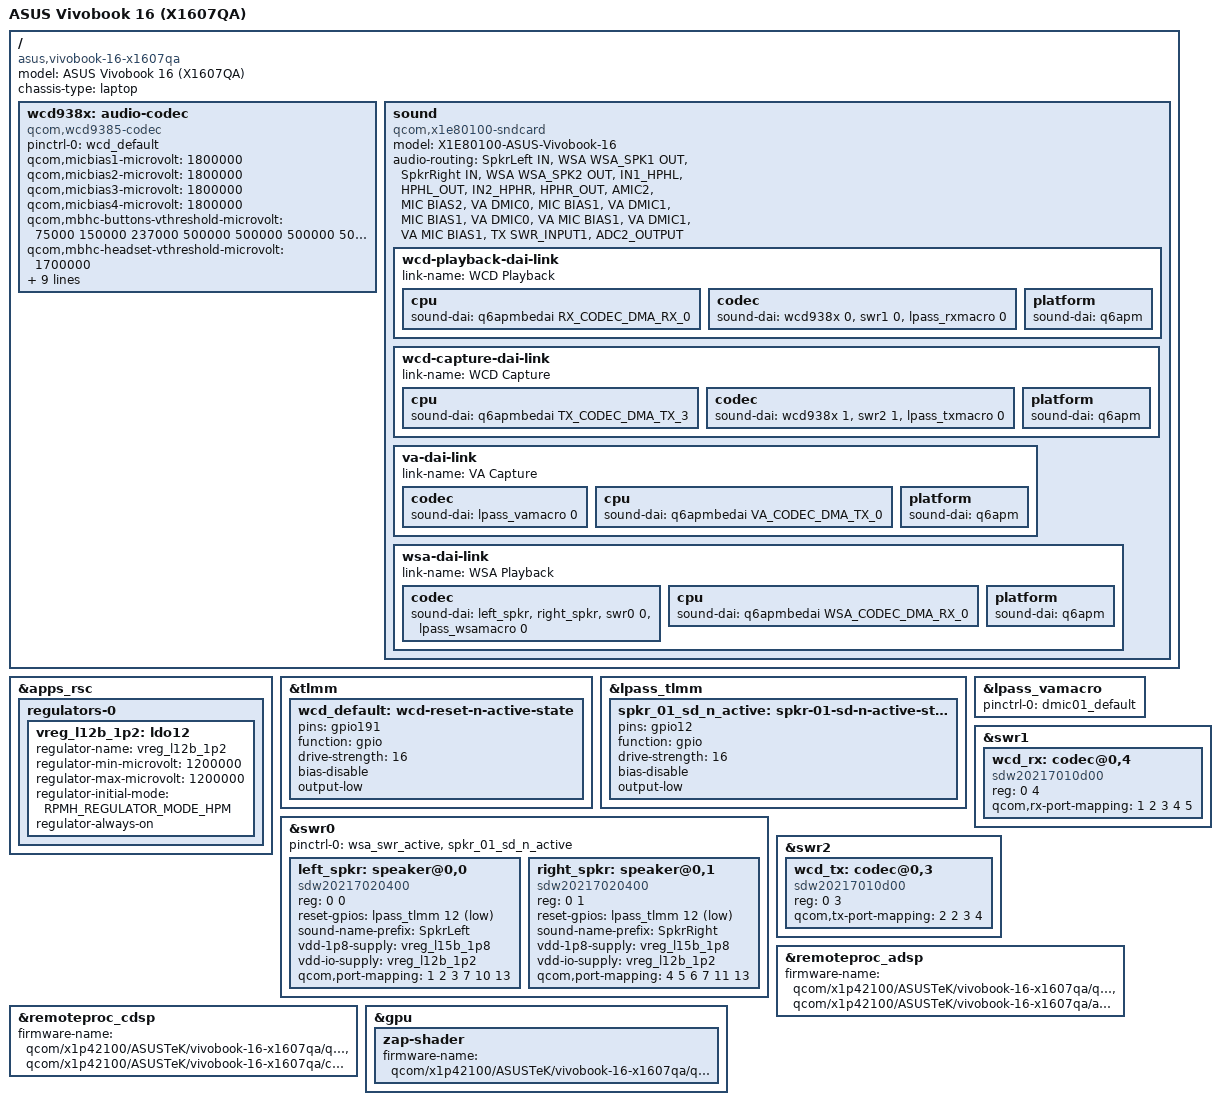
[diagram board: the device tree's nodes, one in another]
// SPDX-License-Identifier: BSD-3-Clause
/* Hybrid device tree for ASUS Vivobook 16 X1607QA (X1P-42-100).
 * Base: proven x1p42100-asus-vivobook-s15 (panel, USB, boot path).
 * Transplanted from x126100-asus-vivobook-16: audio stack
 * (WCD9385 codec, WSA8845 speakers, soundwire, sndcard) + firmware paths.
 */

/dts-v1/;

#include "purwa.dtsi"
#include "x1-asus-vivobook-s15.dtsi"

/ {
	model = "ASUS Vivobook 16 (X1607QA)";
	compatible = "asus,vivobook-16-x1607qa", "qcom,x1p42100";
	chassis-type = "laptop";
};

/* Speaker VDD-IO rail, from vivobook-16 board regulators */
&apps_rsc {
	regulators-0 {
		vreg_l12b_1p2: ldo12 {
			regulator-name = "vreg_l12b_1p2";
			regulator-min-microvolt = <1200000>;
			regulator-max-microvolt = <1200000>;
			regulator-initial-mode = <RPMH_REGULATOR_MODE_HPM>;
			regulator-always-on;
		};
	};
};

&tlmm {
	wcd_default: wcd-reset-n-active-state {
		pins = "gpio191";
		function = "gpio";
		drive-strength = <16>;
		bias-disable;
		output-low;
	};
};

&lpass_tlmm {
	spkr_01_sd_n_active: spkr-01-sd-n-active-state {
		pins = "gpio12";
		function = "gpio";
		drive-strength = <16>;
		bias-disable;
		output-low;
	};
};

&lpass_vamacro {
	pinctrl-0 = <&dmic01_default>;
	pinctrl-names = "default";
};

/ {
	wcd938x: audio-codec {
		compatible = "qcom,wcd9385-codec";

		pinctrl-0 = <&wcd_default>;
		pinctrl-names = "default";

		qcom,micbias1-microvolt = <1800000>;
		qcom,micbias2-microvolt = <1800000>;
		qcom,micbias3-microvolt = <1800000>;
		qcom,micbias4-microvolt = <1800000>;
		qcom,mbhc-buttons-vthreshold-microvolt =
			<75000 150000 237000 500000 500000 500000 500000 500000>;
		qcom,mbhc-headset-vthreshold-microvolt = <1700000>;
		qcom,mbhc-headphone-vthreshold-microvolt = <50000>;
		qcom,rx-device = <&wcd_rx>;
		qcom,tx-device = <&wcd_tx>;

		reset-gpios = <&tlmm 191 GPIO_ACTIVE_LOW>;

		vdd-buck-supply = <&vreg_l15b_1p8>;
		vdd-rxtx-supply = <&vreg_l15b_1p8>;
		vdd-io-supply = <&vreg_l15b_1p8>;
		vdd-mic-bias-supply = <&vreg_bob1>;

		#sound-dai-cells = <1>;
	};

	sound {
		compatible = "qcom,x1e80100-sndcard";
		model = "X1E80100-ASUS-Vivobook-16";
		audio-routing = "SpkrLeft IN", "WSA WSA_SPK1 OUT",
						"SpkrRight IN", "WSA WSA_SPK2 OUT",
						"IN1_HPHL", "HPHL_OUT",
						"IN2_HPHR", "HPHR_OUT",
						"AMIC2", "MIC BIAS2",
						"VA DMIC0", "MIC BIAS1",
						"VA DMIC1", "MIC BIAS1",
						"VA DMIC0", "VA MIC BIAS1",
						"VA DMIC1", "VA MIC BIAS1",
						"TX SWR_INPUT1", "ADC2_OUTPUT";

		wcd-playback-dai-link {
			link-name = "WCD Playback";

			cpu {
				sound-dai = <&q6apmbedai RX_CODEC_DMA_RX_0>;
			};

			codec {
				sound-dai = <&wcd938x 0>, <&swr1 0>, <&lpass_rxmacro 0>;
			};

			platform {
				sound-dai = <&q6apm>;
			};
		};

		wcd-capture-dai-link {
			link-name = "WCD Capture";

			cpu {
				sound-dai = <&q6apmbedai TX_CODEC_DMA_TX_3>;
			};

			codec {
				sound-dai = <&wcd938x 1>, <&swr2 1>, <&lpass_txmacro 0>;
			};

			platform {
				sound-dai = <&q6apm>;
			};
		};

		va-dai-link {
			link-name = "VA Capture";

			codec {
				sound-dai = <&lpass_vamacro 0>;
			};

			cpu {
				sound-dai = <&q6apmbedai VA_CODEC_DMA_TX_0>;
			};

			platform {
				sound-dai = <&q6apm>;
			};
		};

		wsa-dai-link {
			link-name = "WSA Playback";

			codec {
				sound-dai = <&left_spkr>, <&right_spkr>,
							<&swr0 0>, <&lpass_wsamacro 0>;
			};

			cpu {
				sound-dai = <&q6apmbedai WSA_CODEC_DMA_RX_0>;
			};

			platform {
				sound-dai = <&q6apm>;
			};
		};
	};
};

&swr0 {
	status = "okay";

	pinctrl-0 = <&wsa_swr_active>, <&spkr_01_sd_n_active>;
	pinctrl-names = "default";

	/* WSA8845, Left Speaker */
	left_spkr: speaker@0,0 {
		compatible = "sdw20217020400";
		reg = <0 0>;
		reset-gpios = <&lpass_tlmm 12 GPIO_ACTIVE_LOW>;
		#sound-dai-cells = <0>;
		sound-name-prefix = "SpkrLeft";
		vdd-1p8-supply = <&vreg_l15b_1p8>;
		vdd-io-supply = <&vreg_l12b_1p2>;
		qcom,port-mapping = <1 2 3 7 10 13>;
	};

	/* WSA8845, Right Speaker */
	right_spkr: speaker@0,1 {
		compatible = "sdw20217020400";
		reg = <0 1>;
		reset-gpios = <&lpass_tlmm 12 GPIO_ACTIVE_LOW>;
		#sound-dai-cells = <0>;
		sound-name-prefix = "SpkrRight";
		vdd-1p8-supply = <&vreg_l15b_1p8>;
		vdd-io-supply = <&vreg_l12b_1p2>;
		qcom,port-mapping = <4 5 6 7 11 13>;
	};
};

&swr1 {
	status = "okay";

	/* WCD9385 RX */
	wcd_rx: codec@0,4 {
		compatible = "sdw20217010d00";
		reg = <0 4>;
		qcom,rx-port-mapping = <1 2 3 4 5>;
	};
};

&swr2 {
	status = "okay";

	/* WCD9385 TX */
	wcd_tx: codec@0,3 {
		compatible = "sdw20217010d00";
		reg = <0 3>;
		qcom,tx-port-mapping = <2 2 3 4>;
	};
};

&remoteproc_adsp {
	firmware-name = "qcom/x1p42100/ASUSTeK/vivobook-16-x1607qa/qcadsp8380.mbn",
					"qcom/x1p42100/ASUSTeK/vivobook-16-x1607qa/adsp_dtbs.elf";

	status = "okay";
};

&remoteproc_cdsp {
	firmware-name = "qcom/x1p42100/ASUSTeK/vivobook-16-x1607qa/qccdsp8380.mbn",
					"qcom/x1p42100/ASUSTeK/vivobook-16-x1607qa/cdsp_dtbs.elf";

	status = "okay";
};

&gpu {
	status = "okay";

	zap-shader {
		firmware-name = "qcom/x1p42100/ASUSTeK/vivobook-16-x1607qa/qcdxkmsucpurwa.mbn";
	};
};
